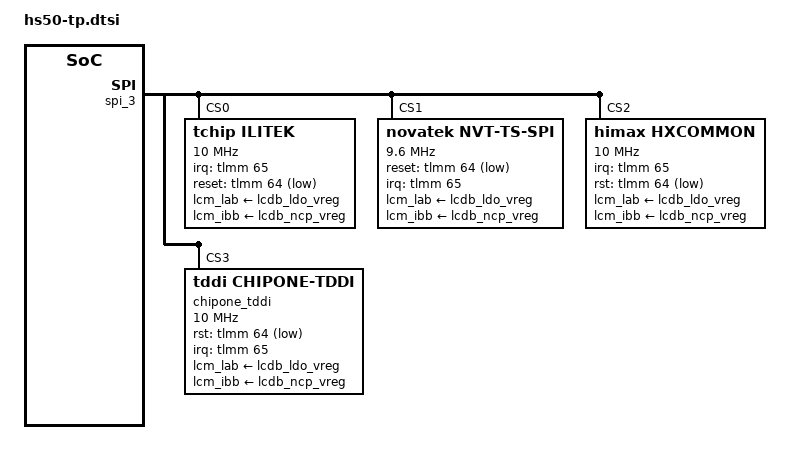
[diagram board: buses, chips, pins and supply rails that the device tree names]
&i2c_3{
	status = "disable";
};
&spi_3{
	status = "ok";
	ilitek@0{
		compatible = "tchip,ilitek";
		reg = <0x0>;
		/* HS70 add for SR-ZQL1871-01-177 by gaozhengwei at 2019/11/02 start */
		lcm_lab-supply = <&lcdb_ldo_vreg>;//Adding Power Properties
		lcm_ibb-supply = <&lcdb_ncp_vreg>;
		/* HS70 add for SR-ZQL1871-01-177 by gaozhengwei at 2019/11/02 end */
		spi-max-frequency = <10000000>;
		interrupt-parent = <&tlmm>;
		interrupts = <65 0x02>;
		touch,irq-gpio = <&tlmm 65 0x02>;
		touch,reset-gpio = <&tlmm 64 0x01>;
		/* HS70 code for HS70-133 by liufurong at 2019/10/31 start */
		pinctrl-names = "default","int-output-high","int-output-low","int-input";
		pinctrl-0 = <&ts_int_default>;
		pinctrl-1 = <&ts_int_output_high>;
		pinctrl-2 = <&ts_int_output_low>;
		pinctrl-3 = <&ts_int_input>;
		/* HS70 code for HS70-133 by liufurong at 2019/10/31 end */
	};
	/*HS50 code for SR-QL3095-01-358 by yuanliding at 2020/07/31 start*/
	/* Novatek device tree node */
	novatek@1 {
		compatible = "novatek,NVT-ts-spi";
		reg = <1>; //Same as CS ID
		status = "ok";

		spi-max-frequency = <9600000>;	//4800000,9600000,15000000,19200000
		novatek,reset-gpio = <&tlmm 64 0x01>;
		novatek,irq-gpio = <&tlmm 65 0x02>;
		lcm_lab-supply = <&lcdb_ldo_vreg>;//Adding Power Properties
		lcm_ibb-supply = <&lcdb_ncp_vreg>;

		/* 525 */
		//novatek,swrst-n8-addr = <0x01F01A>;

		/* 672A, 525B, 675, 526, 672C */
		novatek,swrst-n8-addr = <0x03F0FE>;
		novatek,spi-rd-fast-addr = <0x03F310>;

		/* MP */
		novatek,mp-support-dt;

		novatek-mp-criteria-7211@0 {
			#address-cells = <1>;
			#size-cells = <0>;
			compatible = "novatek-mp-criteria-7211";

			/* MP Config */
			IC_X_CFG_SIZE = <18>;
			IC_Y_CFG_SIZE = <32>;
			IC_KEY_CFG_SIZE = <4>;
			X_Channel = <18>;
			Y_Channel = <32>;
			AIN_X = <0 1 2 3 4 5 6 7 8 9 10 11 12 13 14 15 16 17>;
			AIN_Y = <0 1 2 3 4 5 6 7 8 9 10 11 12 13 14 15 16 17
						18 19 20 21 22 23 24 25 26 27 28 29 30 31>;
			AIN_KEY = <0 1 2 0xFF>;

			/* MP Criteria */
			PS_Config_Lmt_Short_Rawdata_P = <
				14008 14008 14008 14008 14008 14008 14008 14008 14008 14008 14008 14008 14008 14008 14008 14008 14008 14008
				14008 14008 14008 14008 14008 14008 14008 14008 14008 14008 14008 14008 14008 14008 14008 14008 14008 14008
				14008 14008 14008 14008 14008 14008 14008 14008 14008 14008 14008 14008 14008 14008 14008 14008 14008 14008
				14008 14008 14008 14008 14008 14008 14008 14008 14008 14008 14008 14008 14008 14008 14008 14008 14008 14008
				14008 14008 14008 14008 14008 14008 14008 14008 14008 14008 14008 14008 14008 14008 14008 14008 14008 14008
				14008 14008 14008 14008 14008 14008 14008 14008 14008 14008 14008 14008 14008 14008 14008 14008 14008 14008
				14008 14008 14008 14008 14008 14008 14008 14008 14008 14008 14008 14008 14008 14008 14008 14008 14008 14008
				14008 14008 14008 14008 14008 14008 14008 14008 14008 14008 14008 14008 14008 14008 14008 14008 14008 14008
				14008 14008 14008 14008 14008 14008 14008 14008 14008 14008 14008 14008 14008 14008 14008 14008 14008 14008
				14008 14008 14008 14008 14008 14008 14008 14008 14008 14008 14008 14008 14008 14008 14008 14008 14008 14008
				14008 14008 14008 14008 14008 14008 14008 14008 14008 14008 14008 14008 14008 14008 14008 14008 14008 14008
				14008 14008 14008 14008 14008 14008 14008 14008 14008 14008 14008 14008 14008 14008 14008 14008 14008 14008
				14008 14008 14008 14008 14008 14008 14008 14008 14008 14008 14008 14008 14008 14008 14008 14008 14008 14008
				14008 14008 14008 14008 14008 14008 14008 14008 14008 14008 14008 14008 14008 14008 14008 14008 14008 14008
				14008 14008 14008 14008 14008 14008 14008 14008 14008 14008 14008 14008 14008 14008 14008 14008 14008 14008
				14008 14008 14008 14008 14008 14008 14008 14008 14008 14008 14008 14008 14008 14008 14008 14008 14008 14008
				14008 14008 14008 14008 14008 14008 14008 14008 14008 14008 14008 14008 14008 14008 14008 14008 14008 14008
				14008 14008 14008 14008 14008 14008 14008 14008 14008 14008 14008 14008 14008 14008 14008 14008 14008 14008
				14008 14008 14008 14008 14008 14008 14008 14008 14008 14008 14008 14008 14008 14008 14008 14008 14008 14008
				14008 14008 14008 14008 14008 14008 14008 14008 14008 14008 14008 14008 14008 14008 14008 14008 14008 14008
				14008 14008 14008 14008 14008 14008 14008 14008 14008 14008 14008 14008 14008 14008 14008 14008 14008 14008
				14008 14008 14008 14008 14008 14008 14008 14008 14008 14008 14008 14008 14008 14008 14008 14008 14008 14008
				14008 14008 14008 14008 14008 14008 14008 14008 14008 14008 14008 14008 14008 14008 14008 14008 14008 14008
				14008 14008 14008 14008 14008 14008 14008 14008 14008 14008 14008 14008 14008 14008 14008 14008 14008 14008
				14008 14008 14008 14008 14008 14008 14008 14008 14008 14008 14008 14008 14008 14008 14008 14008 14008 14008
				14008 14008 14008 14008 14008 14008 14008 14008 14008 14008 14008 14008 14008 14008 14008 14008 14008 14008
				14008 14008 14008 14008 14008 14008 14008 14008 14008 14008 14008 14008 14008 14008 14008 14008 14008 14008
				14008 14008 14008 14008 14008 14008 14008 14008 14008 14008 14008 14008 14008 14008 14008 14008 14008 14008
				14008 14008 14008 14008 14008 14008 14008 14008 14008 14008 14008 14008 14008 14008 14008 14008 14008 14008
				14008 14008 14008 14008 14008 14008 14008 14008 14008 14008 14008 14008 14008 14008 14008 14008 14008 14008
				14008 14008 14008 14008 14008 14008 14008 14008 14008 14008 14008 14008 14008 14008 14008 14008 14008 14008
				14008 14008 14008 14008 14008 14008 14008 14008 14008 14008 14008 14008 14008 14008 14008 14008 14008 14008
				14008 14008 14008>;

			PS_Config_Lmt_Short_Rawdata_N = <
				11376	11376	11376	11376	11376	11376	11376	11376	11376	11376	11376	11376	11376	11376	11376	11376	11376	11376
				11376	11376	11376	11376	11376	11376	11376	11376	11376	11376	11376	11376	11376	11376	11376	11376	11376	11376
				11376	11376	11376	11376	11376	11376	11376	11376	11376	11376	11376	11376	11376	11376	11376	11376	11376	11376
				11376	11376	11376	11376	11376	11376	11376	11376	11376	11376	11376	11376	11376	11376	11376	11376	11376	11376
				11376	11376	11376	11376	11376	11376	11376	11376	11376	11376	11376	11376	11376	11376	11376	11376	11376	11376
				11376	11376	11376	11376	11376	11376	11376	11376	11376	11376	11376	11376	11376	11376	11376	11376	11376	11376
				11376	11376	11376	11376	11376	11376	11376	11376	11376	11376	11376	11376	11376	11376	11376	11376	11376	11376
				11376	11376	11376	11376	11376	11376	11376	11376	11376	11376	11376	11376	11376	11376	11376	11376	11376	11376
				11376	11376	11376	11376	11376	11376	11376	11376	11376	11376	11376	11376	11376	11376	11376	11376	11376	11376
				11376	11376	11376	11376	11376	11376	11376	11376	11376	11376	11376	11376	11376	11376	11376	11376	11376	11376
				11376	11376	11376	11376	11376	11376	11376	11376	11376	11376	11376	11376	11376	11376	11376	11376	11376	11376
				11376	11376	11376	11376	11376	11376	11376	11376	11376	11376	11376	11376	11376	11376	11376	11376	11376	11376
				11376	11376	11376	11376	11376	11376	11376	11376	11376	11376	11376	11376	11376	11376	11376	11376	11376	11376
				11376	11376	11376	11376	11376	11376	11376	11376	11376	11376	11376	11376	11376	11376	11376	11376	11376	11376
				11376	11376	11376	11376	11376	11376	11376	11376	11376	11376	11376	11376	11376	11376	11376	11376	11376	11376
				11376	11376	11376	11376	11376	11376	11376	11376	11376	11376	11376	11376	11376	11376	11376	11376	11376	11376
				11376	11376	11376	11376	11376	11376	11376	11376	11376	11376	11376	11376	11376	11376	11376	11376	11376	11376
				11376	11376	11376	11376	11376	11376	11376	11376	11376	11376	11376	11376	11376	11376	11376	11376	11376	11376
				11376	11376	11376	11376	11376	11376	11376	11376	11376	11376	11376	11376	11376	11376	11376	11376	11376	11376
				11376	11376	11376	11376	11376	11376	11376	11376	11376	11376	11376	11376	11376	11376	11376	11376	11376	11376
				11376	11376	11376	11376	11376	11376	11376	11376	11376	11376	11376	11376	11376	11376	11376	11376	11376	11376
				11376	11376	11376	11376	11376	11376	11376	11376	11376	11376	11376	11376	11376	11376	11376	11376	11376	11376
				11376	11376	11376	11376	11376	11376	11376	11376	11376	11376	11376	11376	11376	11376	11376	11376	11376	11376
				11376	11376	11376	11376	11376	11376	11376	11376	11376	11376	11376	11376	11376	11376	11376	11376	11376	11376
				11376	11376	11376	11376	11376	11376	11376	11376	11376	11376	11376	11376	11376	11376	11376	11376	11376	11376
				11376	11376	11376	11376	11376	11376	11376	11376	11376	11376	11376	11376	11376	11376	11376	11376	11376	11376
				11376	11376	11376	11376	11376	11376	11376	11376	11376	11376	11376	11376	11376	11376	11376	11376	11376	11376
				11376	11376	11376	11376	11376	11376	11376	11376	11376	11376	11376	11376	11376	11376	11376	11376	11376	11376
				11376	11376	11376	11376	11376	11376	11376	11376	11376	11376	11376	11376	11376	11376	11376	11376	11376	11376
				11376	11376	11376	11376	11376	11376	11376	11376	11376	11376	11376	11376	11376	11376	11376	11376	11376	11376
				11376	11376	11376	11376	11376	11376	11376	11376	11376	11376	11376	11376	11376	11376	11376	11376	11376	11376
				11376	11376	11376	11376	11376	11376	11376	11376	11376	11376	11376	11376	11376	11376	11376	11376	11376	11376
				10000 10000 10000>;

			PS_Config_Lmt_Open_Rawdata_P = <
				3259	3344	3360	3420	3465	3465	3504	3507	65535	65535	3434	3428	3393	3396	3402	3399	3395	3301
				3178	3266	3334	3410	3476	3486	3486	3487	3462	3453	3493	3486	3487	3477	3466	3449	3395	3299
				3264	3341	3409	3491	3557	3568	3565	3570	3535	3416	3456	3458	3459	3453	3442	3431	3375	3306
				3242	3305	3371	3453	3525	3539	3537	3540	3504	3459	3505	3505	3507	3502	3493	3480	3432	3369
				3285	3354	3420	3502	3572	3586	3582	3586	3546	3421	3466	3467	3467	3465	3452	3439	3396	3337
				3260	3320	3383	3467	3540	3563	3563	3567	3528	3480	3528	3529	3530	3529	3515	3501	3463	3403
				3288	3383	3431	3467	3488	3497	3516	3518	3515	3565	3568	3572	3553	3530	3449	3357	3281	3189
				3311	3402	3451	3486	3502	3516	3526	3535	3532	3582	3585	3582	3571	3558	3486	3395	3322	3235
				3291	3382	3430	3467	3484	3500	3504	3511	3508	3560	3565	3563	3558	3547	3477	3385	3315	3231
				3327	3416	3469	3502	3521	3536	3540	3542	3537	3593	3602	3606	3602	3593	3521	3430	3361	3276
				3343	3425	3481	3516	3530	3542	3549	3547	3544	3588	3595	3598	3595	3589	3528	3442	3376	3295
				3381	3460	3518	3554	3570	3584	3585	3586	3585	3626	3633	3634	3637	3630	3571	3487	3421	3343
				3383	3463	3539	3571	3592	3600	3605	3606	3607	3619	3623	3623	3624	3620	3565	3487	3404	3327
				3407	3488	3563	3598	3610	3623	3626	3627	3627	3652	3658	3661	3661	3656	3612	3532	3449	3372
				3407	3481	3551	3582	3593	3602	3607	3610	3607	3640	3648	3651	3648	3651	3606	3537	3460	3388
				3425	3504	3571	3607	3617	3630	3630	3634	3630	3661	3668	3672	3675	3673	3637	3570	3493	3421
				3434	3509	3577	3607	3620	3628	3626	3628	3626	3628	3640	3642	3644	3644	3610	3546	3472	3403
				3463	3536	3598	3631	3642	3649	3647	3649	3644	3669	3679	3683	3686	3684	3655	3593	3523	3458
				3473	3540	3603	3628	3642	3651	3651	3647	3645	3640	3654	3658	3663	3661	3638	3584	3523	3456
				3509	3574	3633	3663	3673	3677	3677	3676	3673	3668	3682	3687	3691	3691	3675	3619	3558	3494
				3502	3565	3623	3652	3662	3668	3665	3662	3656	3631	3648	3649	3655	3654	3641	3593	3537	3477
				3505	3563	3617	3647	3654	3661	3658	3655	3651	3670	3687	3690	3696	3696	3689	3641	3586	3529
				3544	3605	3648	3689	3697	3704	3700	3696	3687	3630	3648	3654	3659	3658	3659	3631	3589	3539
				3528	3582	3626	3662	3673	3680	3676	3673	3665	3669	3687	3691	3698	3698	3700	3677	3637	3591
				3556	3603	3642	3679	3691	3696	3691	3689	3682	3627	3644	3648	3654	3654	3656	3640	3599	3560
				3539	3585	3623	3656	3670	3672	3669	3663	3658	3672	3689	3696	3701	3704	3705	3693	3658	3624
				3585	3630	3662	3693	3705	3707	3708	3704	3698	3630	3642	3648	3645	3649	3649	3638	3609	3577
				3577	3617	3652	3677	3690	3691	3691	3686	3683	3694	3708	3715	3715	3718	3718	3712	3683	3655
				3617	3656	3683	3705	3717	3717	3714	3711	3708	3648	3662	3669	3669	3673	3675	3672	3647	3617
				3602	3638	3662	3680	3690	3691	3690	3684	3680	3686	3698	3705	3705	3710	3714	3712	3693	3673
				2872	3672	3690	3701	3708	3708	3705	3700	3698	3645	3659	3665	3668	3672	3675	3673	3659	2854
				2989	3592	3672	3672	3679	3683	3680	3677	3696	3728	3724	3726	3729	3731	3731	3731	3628	3024
				5120 5120 5120>;

			PS_Config_Lmt_Open_Rawdata_N = <
				1396	1433	1440	1465	1485	1485	1501	1503	(-65535)	(-65535)	1471	1469	1454	1455	1458	1456	1455	1414
				1362	1399	1429	1461	1489	1494	1494	1494	1483	1480	1497	1494	1494	1490	1485	1478	1455	1414        
				1399	1432	1461	1496	1524	1529	1528	1530	1515	1464	1481	1482	1482	1480	1475	1470	1446	1417        
				1389	1416	1444	1480	1510	1516	1516	1517	1501	1482	1502	1502	1503	1501	1497	1491	1471	1444        
				1408	1437	1465	1501	1531	1537	1535	1537	1519	1466	1485	1486	1486	1485	1479	1474	1455	1430        
				1397	1423	1450	1486	1517	1527	1527	1528	1512	1491	1512	1512	1513	1512	1506	1500	1484	1458        
				1409	1450	1470	1486	1495	1498	1507	1507	1506	1528	1529	1531	1522	1513	1478	1438	1406	1366        
				1419	1458	1479	1494	1501	1507	1511	1515	1513	1535	1536	1535	1530	1525	1494	1455	1423	1386        
				1410	1449	1470	1486	1493	1500	1501	1504	1503	1525	1528	1527	1525	1520	1490	1450	1420	1384        
				1426	1464	1486	1501	1509	1515	1517	1518	1516	1540	1543	1545	1543	1540	1509	1470	1440	1404        
				1432	1468	1492	1507	1513	1518	1521	1520	1519	1537	1540	1542	1540	1538	1512	1475	1447	1412        
				1449	1483	1507	1523	1530	1536	1536	1537	1536	1554	1557	1557	1558	1555	1530	1494	1466	1432        
				1450	1484	1516	1530	1539	1543	1545	1545	1546	1551	1552	1552	1553	1551	1528	1494	1459	1426        
				1460	1495	1527	1542	1547	1552	1554	1554	1554	1565	1567	1569	1569	1567	1548	1513	1478	1445        
				1460	1492	1522	1535	1540	1543	1546	1547	1546	1560	1563	1564	1563	1564	1545	1516	1483	1452        
				1468	1501	1530	1546	1550	1555	1555	1557	1555	1569	1572	1573	1575	1574	1558	1530	1497	1466        
				1471	1504	1533	1546	1551	1555	1554	1555	1554	1555	1560	1561	1561	1561	1547	1519	1488	1458        
				1484	1515	1542	1556	1561	1564	1563	1564	1561	1572	1576	1578	1579	1579	1566	1540	1510	1482        
				1488	1517	1544	1555	1561	1564	1564	1563	1562	1560	1566	1567	1570	1569	1559	1536	1510	1481        
				1504	1531	1557	1570	1574	1576	1576	1575	1574	1572	1578	1580	1582	1582	1575	1551	1525	1497        
				1501	1528	1552	1565	1569	1572	1570	1569	1567	1556	1563	1564	1566	1566	1560	1540	1516	1490        
				1502	1527	1550	1563	1566	1569	1567	1566	1564	1573	1580	1581	1584	1584	1581	1560	1537	1512        
				1519	1545	1563	1581	1584	1587	1585	1584	1580	1555	1563	1566	1568	1567	1568	1556	1538	1516        
				1512	1535	1554	1569	1574	1577	1575	1574	1570	1572	1580	1582	1585	1585	1585	1576	1558	1539        
				1524	1544	1561	1576	1582	1584	1582	1581	1578	1554	1561	1563	1566	1566	1567	1560	1542	1525        
				1516	1536	1552	1567	1573	1573	1572	1570	1567	1573	1581	1584	1586	1587	1588	1582	1567	1553        
				1536	1555	1569	1582	1588	1588	1589	1587	1585	1555	1561	1563	1562	1564	1564	1559	1546	1533        
				1533	1550	1565	1576	1581	1582	1582	1579	1578	1583	1589	1592	1592	1593	1593	1591	1578	1566        
				1550	1567	1578	1588	1593	1593	1591	1590	1589	1563	1569	1572	1572	1574	1575	1573	1563	1550        
				1543	1559	1569	1577	1581	1582	1581	1579	1577	1579	1585	1588	1588	1590	1591	1591	1582	1574        
				1231	1573	1581	1586	1589	1589	1588	1585	1585	1562	1568	1570	1572	1573	1575	1574	1568	1223        
				1281	1539	1573	1573	1576	1578	1577	1576	1584	1597	1596	1597	1598	1599	1599	1599	1555	1296        
				(-511) (-511) (-511)>;

			PS_Config_Lmt_FW_Rawdata_P = <
				2255	2245	2235	2252	2247	2251	2238	2248	65535	65535	2248	2228	2247	2240	2247	2256	2256	2238
				2245	2269	2249	2251	2238	2238	2237	2228	2234	2252	2249	2241	2245	2255	2262	2252	2254	2233
				2255	2226	2231	2234	2237	2226	2235	2241	2230	2251	2231	2241	2230	2235	2228	2237	2259	2228
				2245	2247	2245	2245	2252	2251	2245	2235	2251	2233	2209	2217	2223	2230	2228	2223	2234	2249
				2245	2251	2256	2254	2249	2252	2256	2241	2241	2240	2248	2244	2238	2219	2217	2221	2255	2231
				2235	2245	2231	2242	2241	2242	2242	2266	2279	2241	2247	2251	2259	2245	2270	2259	2282	2219
				2252	2227	2251	2240	2242	2234	2216	2241	2214	2248	2227	2228	2221	2235	2256	2230	2252	2237
				2213	2259	2249	2266	2254	2237	2254	2256	2244	2241	2241	2247	2262	2235	2233	2248	2241	2251
				2235	2242	2254	2258	2252	2256	2256	2266	2262	2256	2254	2252	2235	2262	2252	2251	2248	2244
				2255	2245	2228	2240	2237	2221	2228	2223	2240	2261	2255	2245	2244	2231	2247	2248	2237	2245
				2241	2244	2234	2242	2241	2242	2234	2248	2242	2256	2247	2254	2254	2251	2244	2238	2254	2259
				2235	2256	2237	2237	2235	2245	2230	2226	2255	2235	2237	2247	2242	2224	2220	2247	2226	2244
				2235	2235	2254	2252	2241	2238	2245	2244	2247	2238	2263	2269	2268	2252	2249	2238	2244	2226
				2252	2241	2233	2234	2228	2237	2226	2233	2247	2233	2255	2245	2242	2255	2241	2235	2256	2226
				2230	2238	2242	2237	2230	2221	2230	2238	2235	2230	2231	2237	2237	2230	2217	2228	2247	2254
				2249	2231	2254	2244	2244	2252	2248	2259	2249	2233	2233	2228	2224	2234	2248	2252	2212	2251
				2258	2242	2247	2258	2244	2231	2233	2248	2241	2226	2255	2266	2269	2249	2241	2244	2251	2241
				2261	2254	2228	2233	2234	2244	2240	2228	2240	2249	2258	2237	2242	2270	2259	2263	2244	2241
				2245	2224	2237	2241	2234	2228	2235	2235	2238	2241	2247	2234	2220	2249	2245	2244	2245	2235
				2220	2251	2252	2238	2240	2231	2230	2245	2228	2252	2228	2241	2244	2241	2230	2235	2230	2235
				2227	2235	2251	2237	2247	2240	2247	2247	2237	2273	2245	2258	2244	2251	2233	2241	2244	2262
				2223	2249	2244	2238	2234	2230	2234	2228	2223	2255	2252	2263	2270	2249	2256	2252	2258	2268
				2263	2220	2233	2226	2242	2230	2235	2235	2234	2245	2238	2241	2230	2251	2242	2258	2234	2248
				2262	2227	2247	2248	2255	2258	2256	2247	2227	2235	2231	2242	2238	2213	2227	2213	2234	2221
				2262	2252	2244	2258	2247	2235	2247	2245	2242	2252	2240	2217	2205	2240	2240	2244	2224	2266
				2259	2237	2238	2234	2244	2245	2248	2255	2247	2242	2261	2259	2255	2252	2242	2248	2245	2261
				2238	2238	2256	2256	2256	2268	2268	2235	2249	2240	2235	2248	2248	2242	2247	2251	2252	2242
				2238	2247	2216	2245	2231	2224	2226	2224	2254	2244	2252	2252	2248	2247	2254	2249	2235	2242
				2268	2224	2224	2234	2233	2228	2227	2226	2262	2256	2235	2249	2245	2240	2234	2227	2263	2263
				2234	2263	2251	2245	2258	2251	2240	2242	2241	2223	2240	2245	2245	2238	2228	2227	2240	2261
				2256	2251	2249	2241	2261	2258	2258	2256	2255	2266	2227	2231	2233	2219	2237	2241	2240	2237
				2254	2248	2258	2247	2237	2231	2219	2227	2247	2255	2251	2254	2248	2284	2263	2269	2265	2231
				2560 2560 2560>;

			PS_Config_Lmt_FW_Rawdata_N = <
				966	962	958	965	963	964	959	963	(-65535)	(-65535)	963	955	963	960	963	967	967	959
				962	972	964	964	959	959	958	955	957	965	964	960	962	966	969	965	966	957            
				966	954	956	957	958	954	958	960	955	964	956	960	955	958	955	958	968	955            
				962	963	962	962	965	964	962	958	964	957	946	950	952	955	955	952	957	964            
				962	964	967	966	964	965	967	960	960	960	963	961	959	951	950	952	966	956            
				958	962	956	961	960	961	961	971	976	960	963	964	968	962	973	968	978	951            
				965	954	964	960	961	957	949	960	949	963	954	955	952	958	967	955	965	958            
				948	968	964	971	966	958	966	967	961	960	960	963	969	958	957	963	960	964            
				958	961	966	967	965	967	967	971	969	967	966	965	958	969	965	964	963	961            
				966	962	955	960	958	952	955	952	960	969	966	962	961	956	963	963	958	962            
				960	961	957	961	960	961	957	963	961	967	963	966	966	964	961	959	966	968            
				958	967	958	958	958	962	955	954	966	958	958	963	961	953	951	963	954	961            
				958	958	966	965	960	959	962	961	963	959	970	972	972	965	964	959	961	954            
				965	960	957	957	955	958	954	957	963	957	966	962	961	966	960	958	967	954            
				955	959	961	958	955	952	955	959	958	955	956	958	958	955	950	955	963	966            
				964	956	966	961	961	965	963	968	964	957	957	955	953	957	963	965	948	964            
				967	961	963	967	961	956	957	963	960	954	966	971	972	964	960	961	964	960            
				969	966	955	957	957	961	960	955	960	964	967	958	961	973	968	970	961	960            
				962	953	958	960	957	955	958	958	959	960	963	957	951	964	962	961	962	958            
				951	964	965	959	960	956	955	962	955	965	955	960	961	960	955	958	955	958            
				954	958	964	958	963	960	963	963	958	974	962	967	961	964	957	960	961	969            
				952	964	961	959	957	955	957	955	952	966	965	970	973	964	967	965	967	972            
				970	951	957	954	961	955	958	958	957	962	959	960	955	964	961	967	957	963            
				969	954	963	963	966	967	967	963	954	958	956	961	959	948	954	948	957	952            
				969	965	961	967	963	958	963	962	961	965	960	950	945	960	960	961	953	971            
				968	958	959	957	961	962	963	966	963	961	969	968	966	965	961	963	962	969            
				959	959	967	967	967	972	972	958	964	960	958	963	963	961	963	964	965	961            
				959	963	949	962	956	953	954	953	966	961	965	965	963	963	966	964	958	961            
				972	953	953	957	957	955	954	954	969	967	958	964	962	960	957	954	970	970            
				957	970	964	962	967	964	960	961	960	952	960	962	962	959	955	954	960	969            
				967	964	964	960	969	967	967	967	966	971	954	956	957	951	958	960	960	958            
				966	963	967	963	958	956	951	954	963	966	964	966	963	979	970	972	970	956            
				240 240 240>;

			PS_Config_Lmt_FW_CC_P = <
				93	96	96	96	97	97	97	96	65535	65535	99	100	100	100	99	99	99	97
				95	95	95	95	95	95	95	95	97	102	99	99	99	99	99	99	100	100   
				96	95	95	95	95	95	95	96	99	100	99	99	99	99	99	99	99	100   
				96	95	95	95	95	95	95	95	97	102	99	99	99	99	99	99	100	102   
				96	95	95	96	96	96	96	96	99	102	99	99	99	99	99	99	99	100   
				96	95	95	96	96	96	96	96	99	103	100	100	100	100	100	100	100	102   
				97	96	96	96	96	96	96	96	99	102	100	100	100	99	99	99	99	100   
				100	99	99	99	99	99	99	99	102	104	103	103	103	102	102	102	102	103   
				97	96	96	96	96	96	96	96	99	102	99	99	100	99	99	99	99	100   
				100	99	97	97	97	97	97	97	100	104	102	102	102	102	102	102	102	103   
				97	96	96	96	96	95	96	96	97	102	99	99	99	99	99	99	99	100   
				100	97	97	97	97	97	97	97	100	104	102	102	102	102	102	102	102	103   
				97	96	96	96	96	95	96	96	97	102	99	99	99	99	99	99	99	100   
				100	99	99	99	99	99	99	99	102	104	102	102	102	102	102	102	102	103   
				97	96	96	96	96	96	96	96	99	102	99	99	99	99	99	99	99	100   
				99	97	97	97	97	97	97	97	100	104	102	102	102	102	102	102	102	103   
				97	96	96	96	95	95	95	95	97	102	99	99	99	99	99	99	99	100   
				99	97	97	97	97	97	97	97	100	104	102	102	102	102	102	102	102	104   
				99	96	96	96	96	96	96	96	99	100	99	99	99	99	99	99	99	100   
				100	99	97	99	97	97	97	97	100	103	102	102	102	102	102	102	102	103   
				97	96	96	96	96	96	96	96	97	102	99	99	99	99	99	99	99	102   
				100	99	99	99	99	99	99	99	102	103	102	102	102	102	102	102	102	103   
				97	95	95	95	95	95	95	95	97	99	97	97	97	97	97	97	97	100   
				96	95	95	95	95	95	95	95	97	100	99	99	99	99	99	99	99	102   
				96	95	95	95	95	95	95	95	97	100	97	97	99	97	97	97	99	100   
				97	96	95	96	95	95	95	95	97	100	99	99	99	99	99	99	99	102   
				96	95	95	95	95	95	95	95	97	99	97	97	97	97	97	97	97	99    
				97	96	96	96	96	95	95	95	97	102	99	99	99	99	99	99	100	102   
				97	96	95	96	95	95	95	95	97	100	97	97	97	97	97	97	99	100   
				97	95	95	95	95	95	95	95	97	102	99	99	99	99	99	99	99	102   
				91	95	95	95	95	95	95	95	97	99	97	97	97	97	97	97	97	92    
				91	95	95	93	93	93	95	95	97	102	99	99	99	99	99	99	99	95    
				314 314 314>;

			PS_Config_Lmt_FW_CC_N = <
				42	43	43	43	44	44	44	43	(-65535)	(-65535)	44	45	45	45	44	44	44	44
				42	42	42	42	42	42	42	42	44	45	44	44	44	44	44	44	45	45            
				43	42	42	42	42	42	42	43	44	45	44	44	44	44	44	44	44	45            
				43	42	42	42	42	42	42	42	44	45	44	44	44	44	44	44	45	45            
				43	42	42	43	43	43	43	43	44	45	44	44	44	44	44	44	44	45            
				43	42	42	43	43	43	43	43	44	46	45	45	45	45	45	45	45	45            
				44	43	43	43	43	43	43	43	44	45	45	45	45	44	44	44	44	45            
				45	44	44	44	44	44	44	44	45	47	46	46	46	45	45	45	45	46            
				44	43	43	43	43	43	43	43	44	45	44	44	45	44	44	44	44	45            
				45	44	44	44	44	44	44	44	45	47	45	45	45	45	45	45	45	46            
				44	43	43	43	43	42	43	43	44	45	44	44	44	44	44	44	44	45            
				45	44	44	44	44	44	44	44	45	47	45	45	45	45	45	45	45	46            
				44	43	43	43	43	42	43	43	44	45	44	44	44	44	44	44	44	45            
				45	44	44	44	44	44	44	44	45	47	45	45	45	45	45	45	45	46            
				44	43	43	43	43	43	43	43	44	45	44	44	44	44	44	44	44	45            
				44	44	44	44	44	44	44	44	45	47	45	45	45	45	45	45	45	46            
				44	43	43	43	42	42	42	42	44	45	44	44	44	44	44	44	44	45            
				44	44	44	44	44	44	44	44	45	47	45	45	45	45	45	45	45	47            
				44	43	43	43	43	43	43	43	44	45	44	44	44	44	44	44	44	45            
				45	44	44	44	44	44	44	44	45	46	45	45	45	45	45	45	45	46            
				44	43	43	43	43	43	43	43	44	45	44	44	44	44	44	44	44	45            
				45	44	44	44	44	44	44	44	45	46	45	45	45	45	45	45	45	46            
				44	42	42	42	42	42	42	42	44	44	44	44	44	44	44	44	44	45            
				43	42	42	42	42	42	42	42	44	45	44	44	44	44	44	44	44	45            
				43	42	42	42	42	42	42	42	44	45	44	44	44	44	44	44	44	45            
				44	43	42	43	42	42	42	42	44	45	44	44	44	44	44	44	44	45            
				43	42	42	42	42	42	42	42	44	44	44	44	44	44	44	44	44	44            
				44	43	43	43	43	42	42	42	44	45	44	44	44	44	44	44	45	45            
				44	43	42	43	42	42	42	42	44	45	44	44	44	44	44	44	44	45            
				44	42	42	42	42	42	42	42	44	45	44	44	44	44	44	44	44	45            
				40	42	42	42	42	42	42	42	44	44	44	44	44	44	44	44	44	41            
				40	42	42	42	42	42	42	42	44	45	44	44	44	44	44	44	44	42            
				0 0 0>;

			PS_Config_Lmt_FW_Diff_P = <
				50	50	50	50	50	50	50	50	65535	65535	50	50	50	50	50	50	50	50
				50	50	50	50	50	50	50	50	50	50	50	50	50	50	50	50	50	50    
				50	50	50	50	50	50	50	50	50	50	50	50	50	50	50	50	50	50    
				50	50	50	50	50	50	50	50	50	50	50	50	50	50	50	50	50	50    
				50	50	50	50	50	50	50	50	50	50	50	50	50	50	50	50	50	50    
				50	50	50	50	50	50	50	50	50	50	50	50	50	50	50	50	50	50    
				50	50	50	50	50	50	50	50	50	50	50	50	50	50	50	50	50	50    
				50	50	50	50	50	50	50	50	50	50	50	50	50	50	50	50	50	50    
				50	50	50	50	50	50	50	50	50	50	50	50	50	50	50	50	50	50    
				50	50	50	50	50	50	50	50	50	50	50	50	50	50	50	50	50	50    
				50	50	50	50	50	50	50	50	50	50	50	50	50	50	50	50	50	50    
				50	50	50	50	50	50	50	50	50	50	50	50	50	50	50	50	50	50    
				50	50	50	50	50	50	50	50	50	50	50	50	50	50	50	50	50	50    
				50	50	50	50	50	50	50	50	50	50	50	50	50	50	50	50	50	50    
				50	50	50	50	50	50	50	50	50	50	50	50	50	50	50	50	50	50    
				50	50	50	50	50	50	50	50	50	50	50	50	50	50	50	50	50	50    
				50	50	50	50	50	50	50	50	50	50	50	50	50	50	50	50	50	50    
				50	50	50	50	50	50	50	50	50	50	50	50	50	50	50	50	50	50    
				50	50	50	50	50	50	50	50	50	50	50	50	50	50	50	50	50	50    
				50	50	50	50	50	50	50	50	50	50	50	50	50	50	50	50	50	50    
				50	50	50	50	50	50	50	50	50	50	50	50	50	50	50	50	50	50    
				50	50	50	50	50	50	50	50	50	50	50	50	50	50	50	50	50	50    
				50	50	50	50	50	50	50	50	50	50	50	50	50	50	50	50	50	50    
				50	50	50	50	50	50	50	50	50	50	50	50	50	50	50	50	50	50    
				50	50	50	50	50	50	50	50	50	50	50	50	50	50	50	50	50	50    
				50	50	50	50	50	50	50	50	50	50	50	50	50	50	50	50	50	50    
				50	50	50	50	50	50	50	50	50	50	50	50	50	50	50	50	50	50    
				50	50	50	50	50	50	50	50	50	50	50	50	50	50	50	50	50	50    
				50	50	50	50	50	50	50	50	50	50	50	50	50	50	50	50	50	50    
				50	50	50	50	50	50	50	50	50	50	50	50	50	50	50	50	50	50    
				50	50	50	50	50	50	50	50	50	50	50	50	50	50	50	50	50	50    
				50	50	50	50	50	50	50	50	50	50	50	50	50	50	50	50	50	50    
				75 75 75>;

			PS_Config_Lmt_FW_Diff_N = <
				(-50)	(-50)	(-50)	(-50)	(-50)	(-50)	(-50)	(-50)	(-65535)	(-65535)	(-50)	(-50)	(-50)	(-50)	(-50)	(-50)	(-50)	(-50)
				(-50)	(-50)	(-50)	(-50)	(-50)	(-50)	(-50)	(-50)	(-50)	(-50)	(-50)	(-50)	(-50)	(-50)	(-50)	(-50)	(-50)	(-50)        
				(-50)	(-50)	(-50)	(-50)	(-50)	(-50)	(-50)	(-50)	(-50)	(-50)	(-50)	(-50)	(-50)	(-50)	(-50)	(-50)	(-50)	(-50)        
				(-50)	(-50)	(-50)	(-50)	(-50)	(-50)	(-50)	(-50)	(-50)	(-50)	(-50)	(-50)	(-50)	(-50)	(-50)	(-50)	(-50)	(-50)        
				(-50)	(-50)	(-50)	(-50)	(-50)	(-50)	(-50)	(-50)	(-50)	(-50)	(-50)	(-50)	(-50)	(-50)	(-50)	(-50)	(-50)	(-50)        
				(-50)	(-50)	(-50)	(-50)	(-50)	(-50)	(-50)	(-50)	(-50)	(-50)	(-50)	(-50)	(-50)	(-50)	(-50)	(-50)	(-50)	(-50)        
				(-50)	(-50)	(-50)	(-50)	(-50)	(-50)	(-50)	(-50)	(-50)	(-50)	(-50)	(-50)	(-50)	(-50)	(-50)	(-50)	(-50)	(-50)        
				(-50)	(-50)	(-50)	(-50)	(-50)	(-50)	(-50)	(-50)	(-50)	(-50)	(-50)	(-50)	(-50)	(-50)	(-50)	(-50)	(-50)	(-50)        
				(-50)	(-50)	(-50)	(-50)	(-50)	(-50)	(-50)	(-50)	(-50)	(-50)	(-50)	(-50)	(-50)	(-50)	(-50)	(-50)	(-50)	(-50)        
				(-50)	(-50)	(-50)	(-50)	(-50)	(-50)	(-50)	(-50)	(-50)	(-50)	(-50)	(-50)	(-50)	(-50)	(-50)	(-50)	(-50)	(-50)        
				(-50)	(-50)	(-50)	(-50)	(-50)	(-50)	(-50)	(-50)	(-50)	(-50)	(-50)	(-50)	(-50)	(-50)	(-50)	(-50)	(-50)	(-50)        
				(-50)	(-50)	(-50)	(-50)	(-50)	(-50)	(-50)	(-50)	(-50)	(-50)	(-50)	(-50)	(-50)	(-50)	(-50)	(-50)	(-50)	(-50)        
				(-50)	(-50)	(-50)	(-50)	(-50)	(-50)	(-50)	(-50)	(-50)	(-50)	(-50)	(-50)	(-50)	(-50)	(-50)	(-50)	(-50)	(-50)        
				(-50)	(-50)	(-50)	(-50)	(-50)	(-50)	(-50)	(-50)	(-50)	(-50)	(-50)	(-50)	(-50)	(-50)	(-50)	(-50)	(-50)	(-50)        
				(-50)	(-50)	(-50)	(-50)	(-50)	(-50)	(-50)	(-50)	(-50)	(-50)	(-50)	(-50)	(-50)	(-50)	(-50)	(-50)	(-50)	(-50)        
				(-50)	(-50)	(-50)	(-50)	(-50)	(-50)	(-50)	(-50)	(-50)	(-50)	(-50)	(-50)	(-50)	(-50)	(-50)	(-50)	(-50)	(-50)        
				(-50)	(-50)	(-50)	(-50)	(-50)	(-50)	(-50)	(-50)	(-50)	(-50)	(-50)	(-50)	(-50)	(-50)	(-50)	(-50)	(-50)	(-50)        
				(-50)	(-50)	(-50)	(-50)	(-50)	(-50)	(-50)	(-50)	(-50)	(-50)	(-50)	(-50)	(-50)	(-50)	(-50)	(-50)	(-50)	(-50)        
				(-50)	(-50)	(-50)	(-50)	(-50)	(-50)	(-50)	(-50)	(-50)	(-50)	(-50)	(-50)	(-50)	(-50)	(-50)	(-50)	(-50)	(-50)        
				(-50)	(-50)	(-50)	(-50)	(-50)	(-50)	(-50)	(-50)	(-50)	(-50)	(-50)	(-50)	(-50)	(-50)	(-50)	(-50)	(-50)	(-50)        
				(-50)	(-50)	(-50)	(-50)	(-50)	(-50)	(-50)	(-50)	(-50)	(-50)	(-50)	(-50)	(-50)	(-50)	(-50)	(-50)	(-50)	(-50)        
				(-50)	(-50)	(-50)	(-50)	(-50)	(-50)	(-50)	(-50)	(-50)	(-50)	(-50)	(-50)	(-50)	(-50)	(-50)	(-50)	(-50)	(-50)        
				(-50)	(-50)	(-50)	(-50)	(-50)	(-50)	(-50)	(-50)	(-50)	(-50)	(-50)	(-50)	(-50)	(-50)	(-50)	(-50)	(-50)	(-50)        
				(-50)	(-50)	(-50)	(-50)	(-50)	(-50)	(-50)	(-50)	(-50)	(-50)	(-50)	(-50)	(-50)	(-50)	(-50)	(-50)	(-50)	(-50)        
				(-50)	(-50)	(-50)	(-50)	(-50)	(-50)	(-50)	(-50)	(-50)	(-50)	(-50)	(-50)	(-50)	(-50)	(-50)	(-50)	(-50)	(-50)        
				(-50)	(-50)	(-50)	(-50)	(-50)	(-50)	(-50)	(-50)	(-50)	(-50)	(-50)	(-50)	(-50)	(-50)	(-50)	(-50)	(-50)	(-50)        
				(-50)	(-50)	(-50)	(-50)	(-50)	(-50)	(-50)	(-50)	(-50)	(-50)	(-50)	(-50)	(-50)	(-50)	(-50)	(-50)	(-50)	(-50)        
				(-50)	(-50)	(-50)	(-50)	(-50)	(-50)	(-50)	(-50)	(-50)	(-50)	(-50)	(-50)	(-50)	(-50)	(-50)	(-50)	(-50)	(-50)        
				(-50)	(-50)	(-50)	(-50)	(-50)	(-50)	(-50)	(-50)	(-50)	(-50)	(-50)	(-50)	(-50)	(-50)	(-50)	(-50)	(-50)	(-50)        
				(-50)	(-50)	(-50)	(-50)	(-50)	(-50)	(-50)	(-50)	(-50)	(-50)	(-50)	(-50)	(-50)	(-50)	(-50)	(-50)	(-50)	(-50)        
				(-50)	(-50)	(-50)	(-50)	(-50)	(-50)	(-50)	(-50)	(-50)	(-50)	(-50)	(-50)	(-50)	(-50)	(-50)	(-50)	(-50)	(-50)        
				(-50)	(-50)	(-50)	(-50)	(-50)	(-50)	(-50)	(-50)	(-50)	(-50)	(-50)	(-50)	(-50)	(-50)	(-50)	(-50)	(-50)	(-50)        
				(-75) (-75) (-75)>;

			PS_Config_Diff_Test_Frame = <50>;
		};

		novatek-mp-criteria-721A@1 {
			#address-cells = <1>;
			#size-cells = <0>;
			compatible = "novatek-mp-criteria-721A";

			/* sec cmd test config */
			open_test_spec = <(-511) 5120>;
			short_test_spec = <10000 14008>;
			diff_test_frame = <50>;

			/* MP Config */
			IC_X_CFG_SIZE = <18>;
			IC_Y_CFG_SIZE = <32>;
			IC_KEY_CFG_SIZE = <4>;
			X_Channel = <18>;
			Y_Channel = <32>;
			AIN_X = <0 1 2 3 4 5 6 7 8 9 10 11 12 13 14 15 16 17>;
			AIN_Y = <0 1 2 3 4 5 6 7 8 9 10 11 12 13 14 15 16 17
						18 19 20 21 22 23 24 25 26 27 28 29 30 31>;
			AIN_KEY = <0 1 2 0xFF>;

			/* MP Criteria */
			PS_Config_Lmt_Short_Rawdata_P = <
				14008 14008 14008 14008 14008 14008 14008 14008 14008 14008 14008 14008 14008 14008 14008 14008 14008 14008
				14008 14008 14008 14008 14008 14008 14008 14008 14008 14008 14008 14008 14008 14008 14008 14008 14008 14008
				14008 14008 14008 14008 14008 14008 14008 14008 14008 14008 14008 14008 14008 14008 14008 14008 14008 14008
				14008 14008 14008 14008 14008 14008 14008 14008 14008 14008 14008 14008 14008 14008 14008 14008 14008 14008
				14008 14008 14008 14008 14008 14008 14008 14008 14008 14008 14008 14008 14008 14008 14008 14008 14008 14008
				14008 14008 14008 14008 14008 14008 14008 14008 14008 14008 14008 14008 14008 14008 14008 14008 14008 14008
				14008 14008 14008 14008 14008 14008 14008 14008 14008 14008 14008 14008 14008 14008 14008 14008 14008 14008
				14008 14008 14008 14008 14008 14008 14008 14008 14008 14008 14008 14008 14008 14008 14008 14008 14008 14008
				14008 14008 14008 14008 14008 14008 14008 14008 14008 14008 14008 14008 14008 14008 14008 14008 14008 14008
				14008 14008 14008 14008 14008 14008 14008 14008 14008 14008 14008 14008 14008 14008 14008 14008 14008 14008
				14008 14008 14008 14008 14008 14008 14008 14008 14008 14008 14008 14008 14008 14008 14008 14008 14008 14008
				14008 14008 14008 14008 14008 14008 14008 14008 14008 14008 14008 14008 14008 14008 14008 14008 14008 14008
				14008 14008 14008 14008 14008 14008 14008 14008 14008 14008 14008 14008 14008 14008 14008 14008 14008 14008
				14008 14008 14008 14008 14008 14008 14008 14008 14008 14008 14008 14008 14008 14008 14008 14008 14008 14008
				14008 14008 14008 14008 14008 14008 14008 14008 14008 14008 14008 14008 14008 14008 14008 14008 14008 14008
				14008 14008 14008 14008 14008 14008 14008 14008 14008 14008 14008 14008 14008 14008 14008 14008 14008 14008
				14008 14008 14008 14008 14008 14008 14008 14008 14008 14008 14008 14008 14008 14008 14008 14008 14008 14008
				14008 14008 14008 14008 14008 14008 14008 14008 14008 14008 14008 14008 14008 14008 14008 14008 14008 14008
				14008 14008 14008 14008 14008 14008 14008 14008 14008 14008 14008 14008 14008 14008 14008 14008 14008 14008
				14008 14008 14008 14008 14008 14008 14008 14008 14008 14008 14008 14008 14008 14008 14008 14008 14008 14008
				14008 14008 14008 14008 14008 14008 14008 14008 14008 14008 14008 14008 14008 14008 14008 14008 14008 14008
				14008 14008 14008 14008 14008 14008 14008 14008 14008 14008 14008 14008 14008 14008 14008 14008 14008 14008
				14008 14008 14008 14008 14008 14008 14008 14008 14008 14008 14008 14008 14008 14008 14008 14008 14008 14008
				14008 14008 14008 14008 14008 14008 14008 14008 14008 14008 14008 14008 14008 14008 14008 14008 14008 14008
				14008 14008 14008 14008 14008 14008 14008 14008 14008 14008 14008 14008 14008 14008 14008 14008 14008 14008
				14008 14008 14008 14008 14008 14008 14008 14008 14008 14008 14008 14008 14008 14008 14008 14008 14008 14008
				14008 14008 14008 14008 14008 14008 14008 14008 14008 14008 14008 14008 14008 14008 14008 14008 14008 14008
				14008 14008 14008 14008 14008 14008 14008 14008 14008 14008 14008 14008 14008 14008 14008 14008 14008 14008
				14008 14008 14008 14008 14008 14008 14008 14008 14008 14008 14008 14008 14008 14008 14008 14008 14008 14008
				14008 14008 14008 14008 14008 14008 14008 14008 14008 14008 14008 14008 14008 14008 14008 14008 14008 14008
				14008 14008 14008 14008 14008 14008 14008 14008 14008 14008 14008 14008 14008 14008 14008 14008 14008 14008
				14008 14008 14008 14008 14008 14008 14008 14008 14008 14008 14008 14008 14008 14008 14008 14008 14008 14008
				14008 14008 14008>;

			PS_Config_Lmt_Short_Rawdata_N = <
				11376	11376	11376	11376	11376	11376	11376	11376	11376	11376	11376	11376	11376	11376	11376	11376	11376	11376
				11376	11376	11376	11376	11376	11376	11376	11376	11376	11376	11376	11376	11376	11376	11376	11376	11376	11376
				11376	11376	11376	11376	11376	11376	11376	11376	11376	11376	11376	11376	11376	11376	11376	11376	11376	11376
				11376	11376	11376	11376	11376	11376	11376	11376	11376	11376	11376	11376	11376	11376	11376	11376	11376	11376
				11376	11376	11376	11376	11376	11376	11376	11376	11376	11376	11376	11376	11376	11376	11376	11376	11376	11376
				11376	11376	11376	11376	11376	11376	11376	11376	11376	11376	11376	11376	11376	11376	11376	11376	11376	11376
				11376	11376	11376	11376	11376	11376	11376	11376	11376	11376	11376	11376	11376	11376	11376	11376	11376	11376
				11376	11376	11376	11376	11376	11376	11376	11376	11376	11376	11376	11376	11376	11376	11376	11376	11376	11376
				11376	11376	11376	11376	11376	11376	11376	11376	11376	11376	11376	11376	11376	11376	11376	11376	11376	11376
				11376	11376	11376	11376	11376	11376	11376	11376	11376	11376	11376	11376	11376	11376	11376	11376	11376	11376
				11376	11376	11376	11376	11376	11376	11376	11376	11376	11376	11376	11376	11376	11376	11376	11376	11376	11376
				11376	11376	11376	11376	11376	11376	11376	11376	11376	11376	11376	11376	11376	11376	11376	11376	11376	11376
				11376	11376	11376	11376	11376	11376	11376	11376	11376	11376	11376	11376	11376	11376	11376	11376	11376	11376
				11376	11376	11376	11376	11376	11376	11376	11376	11376	11376	11376	11376	11376	11376	11376	11376	11376	11376
				11376	11376	11376	11376	11376	11376	11376	11376	11376	11376	11376	11376	11376	11376	11376	11376	11376	11376
				11376	11376	11376	11376	11376	11376	11376	11376	11376	11376	11376	11376	11376	11376	11376	11376	11376	11376
				11376	11376	11376	11376	11376	11376	11376	11376	11376	11376	11376	11376	11376	11376	11376	11376	11376	11376
				11376	11376	11376	11376	11376	11376	11376	11376	11376	11376	11376	11376	11376	11376	11376	11376	11376	11376
				11376	11376	11376	11376	11376	11376	11376	11376	11376	11376	11376	11376	11376	11376	11376	11376	11376	11376
				11376	11376	11376	11376	11376	11376	11376	11376	11376	11376	11376	11376	11376	11376	11376	11376	11376	11376
				11376	11376	11376	11376	11376	11376	11376	11376	11376	11376	11376	11376	11376	11376	11376	11376	11376	11376
				11376	11376	11376	11376	11376	11376	11376	11376	11376	11376	11376	11376	11376	11376	11376	11376	11376	11376
				11376	11376	11376	11376	11376	11376	11376	11376	11376	11376	11376	11376	11376	11376	11376	11376	11376	11376
				11376	11376	11376	11376	11376	11376	11376	11376	11376	11376	11376	11376	11376	11376	11376	11376	11376	11376
				11376	11376	11376	11376	11376	11376	11376	11376	11376	11376	11376	11376	11376	11376	11376	11376	11376	11376
				11376	11376	11376	11376	11376	11376	11376	11376	11376	11376	11376	11376	11376	11376	11376	11376	11376	11376
				11376	11376	11376	11376	11376	11376	11376	11376	11376	11376	11376	11376	11376	11376	11376	11376	11376	11376
				11376	11376	11376	11376	11376	11376	11376	11376	11376	11376	11376	11376	11376	11376	11376	11376	11376	11376
				11376	11376	11376	11376	11376	11376	11376	11376	11376	11376	11376	11376	11376	11376	11376	11376	11376	11376
				11376	11376	11376	11376	11376	11376	11376	11376	11376	11376	11376	11376	11376	11376	11376	11376	11376	11376
				11376	11376	11376	11376	11376	11376	11376	11376	11376	11376	11376	11376	11376	11376	11376	11376	11376	11376
				11376	11376	11376	11376	11376	11376	11376	11376	11376	11376	11376	11376	11376	11376	11376	11376	11376	11376
				10000 10000 10000>;

			PS_Config_Lmt_Open_Rawdata_P = <
				2494	2500	2504	2527	2549	2518	2503	2549	65535	65535	2475	2424	2452	2483	2517	2555	2556	2487
				2332	2338	2373	2427	2478	2472	2457	2443	2412	2392	2422	2430	2454	2459	2472	2480	2444	2378
				2389	2392	2429	2490	2548	2542	2522	2511	2472	2399	2426	2440	2459	2471	2482	2493	2455	2401
				2392	2384	2419	2478	2541	2538	2518	2506	2466	2436	2466	2480	2503	2514	2525	2535	2503	2452
				2417	2412	2447	2511	2574	2567	2546	2536	2493	2406	2434	2447	2468	2482	2490	2500	2473	2424
				2417	2409	2443	2503	2569	2577	2556	2545	2500	2466	2503	2515	2535	2550	2557	2566	2548	2499
				2489	2493	2511	2528	2529	2518	2525	2511	2490	2592	2597	2615	2608	2602	2527	2436	2380	2328
				2517	2524	2546	2564	2560	2555	2548	2541	2520	2633	2640	2651	2655	2657	2585	2492	2437	2381
				2528	2539	2566	2587	2581	2577	2563	2557	2536	2644	2651	2661	2674	2676	2605	2510	2455	2398
				2566	2576	2606	2623	2620	2618	2606	2592	2569	2681	2692	2709	2717	2725	2647	2555	2501	2438
				2598	2609	2641	2658	2651	2646	2633	2616	2598	2696	2703	2718	2731	2738	2674	2581	2527	2465
				2632	2640	2679	2697	2692	2685	2664	2650	2634	2732	2738	2755	2780	2790	2725	2627	2571	2510
				2636	2644	2703	2718	2716	2704	2686	2674	2665	2735	2732	2746	2772	2783	2721	2633	2556	2496
				2669	2681	2739	2762	2749	2744	2723	2711	2702	2780	2781	2794	2818	2830	2783	2693	2618	2553
				2711	2721	2781	2800	2790	2773	2762	2749	2738	2793	2793	2807	2822	2846	2797	2717	2637	2573
				2744	2753	2811	2840	2822	2815	2794	2784	2769	2843	2847	2863	2885	2902	2865	2783	2703	2639
				2765	2770	2832	2847	2840	2832	2815	2802	2783	2840	2844	2860	2882	2899	2867	2793	2711	2648
				2790	2797	2853	2870	2863	2854	2835	2823	2804	2885	2889	2906	2924	2941	2909	2842	2766	2699
				2828	2830	2889	2896	2896	2891	2874	2857	2839	2886	2898	2912	2935	2947	2923	2857	2784	2714
				2871	2874	2933	2949	2945	2934	2919	2902	2881	2928	2942	2956	2982	2998	2984	2917	2843	2772
				2888	2884	2938	2958	2954	2942	2927	2910	2888	2931	2945	2958	2983	2998	2993	2924	2854	2787
				2906	2898	2955	2982	2975	2966	2952	2937	2913	2973	2986	3003	3024	3042	3043	2979	2906	2846
				2976	2968	3014	3068	3068	3059	3042	3025	2997	2975	2989	3000	3026	3043	3060	3021	2962	2903
				2997	2983	3026	3073	3080	3068	3049	3032	3005	3033	3050	3063	3087	3103	3119	3095	3033	2975
				3026	3011	3053	3096	3106	3098	3078	3064	3039	3011	3022	3038	3060	3074	3089	3071	3010	2955
				3035	3011	3049	3087	3098	3089	3073	3057	3032	3064	3080	3096	3115	3131	3148	3136	3075	3028
				3101	3077	3108	3145	3157	3147	3145	3134	3112	3080	3091	3106	3109	3126	3138	3126	3073	3031
				3105	3075	3109	3134	3151	3141	3140	3124	3105	3134	3147	3161	3166	3183	3199	3199	3150	3106
				3158	3123	3151	3182	3196	3189	3186	3173	3150	3110	3120	3134	3140	3159	3176	3180	3136	3095
				3141	3105	3133	3159	3175	3166	3164	3151	3130	3147	3158	3172	3175	3194	3214	3227	3187	3147
				2591	3165	3186	3204	3217	3208	3204	3192	3173	3129	3138	3151	3157	3176	3193	3208	3178	2525
				2613	3074	3154	3164	3171	3159	3158	3154	3154	3185	3178	3183	3190	3210	3232	3253	3164	2615
				5120 5120 5120>;

			PS_Config_Lmt_Open_Rawdata_N = <
				1069	1071	1073	1083	1092	1079	1072	1092	(-65535)	(-65535)	1060	1039	1051	1064	1078	1095	1095	1066
				999	1002	1017	1040	1062	1059	1053	1047	1033	1025	1038	1041	1051	1054	1059	1063	1047	1019          
				1024	1025	1041	1067	1092	1089	1081	1076	1059	1028	1039	1045	1054	1059	1063	1068	1052	1029        
				1025	1021	1036	1062	1089	1087	1079	1074	1057	1044	1057	1063	1072	1077	1082	1086	1072	1051        
				1036	1033	1048	1076	1103	1100	1091	1087	1068	1031	1043	1048	1057	1063	1067	1071	1060	1039        
				1036	1032	1047	1072	1101	1104	1095	1090	1071	1057	1072	1078	1086	1093	1096	1099	1092	1071        
				1066	1068	1076	1083	1084	1079	1082	1076	1067	1111	1113	1120	1117	1115	1083	1044	1020	997         
				1078	1081	1091	1099	1097	1095	1092	1089	1080	1128	1131	1136	1138	1138	1108	1068	1044	1020        
				1083	1088	1099	1108	1106	1104	1098	1096	1087	1133	1136	1140	1146	1147	1116	1075	1052	1027        
				1099	1104	1117	1124	1123	1122	1117	1111	1101	1149	1153	1161	1164	1168	1134	1095	1072	1045        
				1113	1118	1132	1139	1136	1134	1128	1121	1113	1155	1158	1165	1170	1173	1146	1106	1083	1056        
				1128	1131	1148	1156	1153	1150	1141	1135	1129	1171	1173	1180	1191	1195	1168	1126	1102	1075        
				1129	1133	1158	1165	1164	1159	1151	1146	1142	1172	1171	1177	1188	1192	1166	1128	1095	1069        
				1144	1149	1174	1183	1178	1176	1167	1162	1158	1191	1192	1197	1207	1213	1192	1154	1122	1094        
				1162	1166	1192	1200	1195	1188	1183	1178	1173	1197	1197	1203	1209	1219	1198	1164	1130	1102        
				1176	1180	1204	1217	1209	1206	1197	1193	1186	1218	1220	1227	1236	1243	1228	1192	1158	1131        
				1185	1187	1213	1220	1217	1213	1206	1201	1192	1217	1219	1225	1235	1242	1228	1197	1162	1135        
				1195	1198	1222	1230	1227	1223	1215	1210	1201	1236	1238	1245	1253	1260	1246	1218	1185	1156        
				1212	1213	1238	1241	1241	1239	1231	1224	1216	1237	1242	1248	1258	1263	1252	1224	1193	1163        
				1230	1231	1257	1264	1262	1257	1251	1243	1234	1255	1261	1267	1278	1285	1279	1250	1218	1188        
				1237	1236	1259	1267	1266	1261	1254	1247	1237	1256	1262	1267	1278	1285	1282	1253	1223	1194        
				1245	1242	1266	1278	1275	1271	1265	1258	1248	1274	1279	1287	1296	1303	1304	1276	1245	1219        
				1275	1272	1291	1315	1315	1311	1303	1296	1284	1275	1281	1285	1297	1304	1311	1294	1269	1244        
				1284	1278	1297	1317	1320	1315	1306	1299	1288	1300	1307	1312	1323	1330	1336	1326	1300	1275        
				1297	1290	1308	1327	1331	1327	1319	1313	1302	1290	1295	1302	1311	1317	1324	1316	1290	1266        
				1300	1290	1306	1323	1327	1324	1317	1310	1299	1313	1320	1327	1335	1342	1349	1344	1318	1297        
				1329	1318	1332	1348	1353	1348	1348	1343	1333	1320	1324	1331	1332	1339	1345	1339	1317	1299        
				1330	1318	1332	1343	1350	1346	1345	1339	1330	1343	1348	1354	1357	1364	1371	1371	1350	1331        
				1353	1338	1350	1363	1369	1366	1365	1360	1350	1333	1337	1343	1345	1354	1361	1363	1344	1326        
				1346	1330	1342	1354	1360	1357	1356	1350	1341	1348	1353	1359	1360	1369	1377	1383	1366	1348        
				1110	1356	1365	1373	1378	1375	1373	1368	1360	1341	1345	1350	1353	1361	1368	1375	1362	1082        
				1120	1317	1351	1356	1359	1354	1353	1351	1351	1365	1362	1364	1367	1375	1385	1394	1356	1120        
				(-511) (-511) (-511)>;

			PS_Config_Lmt_FW_Rawdata_P = <
				2234	2231	2227	2244	2248	2241	2244	2240	65535	65535	2224	2219	2233	2213	2266	2263	2251	2245
				2224	2235	2256	2240	2231	2233	2235	2231	2228	2240	2235	2242	2240	2249	2238	2262	2228	2247
				2238	2254	2240	2252	2254	2251	2256	2244	2254	2224	2235	2247	2252	2244	2251	2254	2259	2223
				2251	2245	2228	2237	2244	2237	2233	2233	2226	2247	2214	2224	2233	2226	2217	2235	2249	2231
				2242	2228	2223	2258	2256	2256	2252	2254	2249	2256	2235	2237	2231	2240	2235	2217	2231	2247
				2251	2244	2242	2248	2251	2247	2244	2221	2230	2220	2247	2251	2248	2238	2247	2255	2279	2224
				2254	2228	2240	2238	2242	2266	2245	2231	2245	2248	2241	2244	2244	2220	2226	2254	2219	2254
				2230	2248	2238	2234	2240	2238	2227	2249	2230	2234	2235	2240	2241	2235	2235	2238	2227	2233
				2242	2223	2272	2237	2259	2254	2254	2226	2241	2235	2233	2237	2235	2241	2255	2252	2263	2227
				2241	2240	2265	2252	2259	2251	2265	2242	2252	2247	2231	2228	2234	2251	2242	2237	2238	2231
				2255	2248	2245	2255	2247	2262	2249	2241	2263	2235	2240	2220	2227	2244	2235	2255	2245	2240
				2261	2223	2228	2244	2233	2235	2237	2238	2248	2230	2255	2244	2249	2251	2248	2230	2234	2259
				2213	2263	2266	2247	2245	2235	2259	2251	2247	2221	2254	2230	2227	2238	2235	2249	2247	2242
				2230	2249	2248	2251	2262	2247	2242	2255	2235	2241	2248	2247	2233	2234	2233	2238	2233	2244
				2234	2252	2245	2249	2241	2233	2238	2235	2217	2242	2268	2252	2248	2251	2254	2244	2249	2205
				2230	2234	2230	2230	2252	2268	2263	2255	2258	2251	2231	2226	2220	2223	2244	2244	2244	2227
				2259	2238	2219	2217	2213	2228	2223	2219	2217	2244	2244	2245	2242	2247	2241	2237	2245	2235
				2249	2235	2234	2248	2238	2247	2249	2230	2238	2234	2252	2248	2265	2255	2240	2248	2245	2242
				2242	2258	2266	2258	2252	2248	2248	2251	2237	2245	2217	2217	2221	2220	2223	2230	2210	2256
				2234	2233	2248	2230	2258	2251	2251	2247	2245	2238	2226	2230	2235	2233	2237	2241	2227	2237
				2242	2247	2237	2242	2240	2228	2231	2234	2224	2252	2234	2245	2244	2228	2242	2240	2251	2231
				2262	2237	2220	2230	2223	2248	2231	2228	2248	2247	2223	2235	2244	2214	2226	2230	2231	2244
				2240	2255	2221	2230	2228	2233	2231	2230	2231	2242	2238	2248	2240	2248	2228	2241	2254	2249
				2238	2242	2230	2231	2230	2231	2230	2241	2227	2241	2242	2237	2244	2223	2230	2235	2258	2235
				2223	2228	2235	2224	2240	2254	2249	2233	2258	2240	2241	2255	2242	2235	2240	2242	2235	2235
				2240	2245	2238	2224	2245	2235	2244	2252	2230	2223	2230	2223	2224	2252	2244	2240	2259	2238
				2227	2245	2238	2242	2228	2234	2240	2233	2242	2235	2255	2255	2248	2259	2244	2233	2241	2230
				2254	2240	2252	2256	2247	2249	2242	2235	2238	2259	2252	2233	2228	2240	2227	2238	2231	2237
				2242	2234	2249	2247	2237	2240	2241	2241	2249	2262	2240	2233	2244	2251	2234	2244	2245	2244
				2259	2226	2241	2231	2242	2244	2234	2214	2223	2216	2220	2233	2231	2226	2237	2248	2254	2235
				2235	2247	2221	2219	2244	2251	2248	2247	2233	2219	2223	2221	2217	2233	2224	2228	2261	2245
				2247	2235	2226	2233	2240	2252	2220	2217	2240	2251	2238	2237	2251	2227	2234	2249	2248	2233
				3750 3750 3750>;

			PS_Config_Lmt_FW_Rawdata_N = <
				957	956	954	961	963	960	961	960	(-65535)	(-65535)	953	951	957	948	971	970	964	962
				953	958	967	960	956	957	958	956	955	960	958	961	960	964	959	969	955	963            
				959	966	960	965	966	964	967	961	966	953	958	963	965	961	964	966	968	952            
				964	962	955	958	961	958	957	957	954	963	949	953	957	954	950	958	964	956            
				961	955	952	967	967	967	965	966	964	967	958	958	956	960	958	950	956	963            
				964	961	961	963	964	963	961	952	955	951	963	964	963	959	963	966	976	953            
				966	955	960	959	961	971	962	956	962	963	960	961	961	951	954	966	951	966            
				955	963	959	957	960	959	954	964	955	957	958	960	960	958	958	959	954	957            
				961	952	973	958	968	966	966	954	960	958	957	958	958	960	966	965	970	954            
				960	960	970	965	968	964	970	961	965	963	956	955	957	964	961	958	959	956            
				966	963	962	966	963	969	964	960	970	958	960	951	954	961	958	966	962	960            
				969	952	955	961	957	958	958	959	963	955	966	961	964	964	963	955	957	968            
				948	970	971	963	962	958	968	964	963	952	966	955	954	959	958	964	963	961            
				955	964	963	964	969	963	961	966	958	960	963	963	957	957	957	959	957	961            
				957	965	962	964	960	957	959	958	950	961	972	965	963	964	966	961	964	945            
				955	957	955	955	965	972	970	966	967	964	956	954	951	952	961	961	961	954            
				968	959	951	950	948	955	952	951	950	961	961	962	961	963	960	958	962	958            
				964	958	957	963	959	963	964	955	959	957	965	963	970	966	960	963	962	961            
				961	967	971	967	965	963	963	964	958	962	950	950	952	951	952	955	947	967            
				957	957	963	955	967	964	964	963	962	959	954	955	958	957	958	960	954	958            
				961	963	958	961	960	955	956	957	953	965	957	962	961	955	961	960	964	956            
				969	958	951	955	952	963	956	955	963	963	952	958	961	949	954	955	956	961            
				960	966	952	955	955	957	956	955	956	961	959	963	960	963	955	960	966	964            
				959	961	955	956	955	956	955	960	954	960	961	958	961	952	955	958	967	958            
				952	955	958	953	960	966	964	957	967	960	960	966	961	958	960	961	958	958            
				960	962	959	953	962	958	961	965	955	952	955	952	953	965	961	960	968	959            
				954	962	959	961	955	957	960	957	961	958	966	966	963	968	961	957	960	955            
				966	960	965	967	963	964	961	958	959	968	965	957	955	960	954	959	956	958            
				961	957	964	963	958	960	960	960	964	969	960	957	961	964	957	961	962	961            
				968	954	960	956	961	961	957	949	952	949	951	957	956	954	958	963	966	958            
				958	963	952	951	961	964	963	963	957	951	952	952	950	957	953	955	969	962            
				963	958	954	957	960	965	951	950	960	964	959	958	964	954	957	964	963	957            
				240 240 240>;

			PS_Config_Lmt_FW_CC_P = <
				89	89	89	91	91	91	92	92	65535	65535	95	95	95	93	93	93	93	93
				93	92	92	92	92	92	92	92	95	97	96	96	96	96	96	96	97	97    
				93	92	92	92	92	92	92	92	95	97	95	95	95	95	95	95	96	97    
				93	92	92	92	93	93	93	93	96	99	96	96	96	96	96	96	97	99    
				95	93	92	93	93	93	93	93	96	97	96	96	96	96	96	96	97	99    
				95	93	93	93	93	93	95	95	97	99	96	96	96	96	96	96	97	99    
				96	95	93	93	93	93	93	93	96	100	97	97	97	97	96	96	96	97    
				97	96	96	96	95	95	96	96	99	103	100	100	100	100	100	99	99	100   
				96	95	93	95	93	93	95	95	96	100	97	97	97	97	97	96	96	99    
				99	97	96	96	96	96	96	96	99	103	100	102	102	100	100	99	100	102   
				96	95	93	93	93	93	93	93	96	100	97	99	97	97	97	96	97	99    
				99	97	96	97	96	96	96	96	99	103	100	100	100	100	100	99	100	102   
				96	95	95	95	95	95	95	95	96	100	99	99	99	99	99	97	97	99    
				99	97	97	97	96	96	97	97	100	104	102	102	102	102	102	100	102	103   
				96	95	95	95	95	95	95	95	97	100	99	99	99	99	99	97	99	100   
				99	97	97	97	97	97	97	97	100	103	102	102	102	102	100	100	100	103   
				96	95	95	95	95	95	95	95	97	100	99	99	99	99	99	97	99	100   
				99	97	97	97	97	97	97	97	100	103	102	102	102	102	102	102	102	103   
				97	96	95	96	95	95	95	95	97	102	99	99	100	99	99	99	99	100   
				100	99	97	97	97	97	97	97	100	103	102	102	102	102	102	102	102	103   
				97	96	96	96	96	95	96	96	97	102	99	99	99	99	99	99	99	102   
				100	99	99	99	99	97	97	99	100	104	102	102	102	102	102	102	103	104   
				97	95	95	95	95	95	95	95	97	100	97	97	99	97	99	99	99	100   
				97	95	95	95	95	95	95	95	97	102	99	99	99	99	99	99	100	102   
				97	96	95	96	95	95	95	95	97	100	99	99	99	99	99	99	99	102   
				97	96	96	96	96	95	95	95	97	100	99	99	99	99	99	99	99	102   
				97	96	96	96	96	95	95	95	97	100	99	99	99	99	99	99	99	102   
				96	95	95	95	95	93	93	95	96	100	99	99	99	99	99	99	100	102   
				97	96	95	95	95	95	95	95	97	100	99	99	99	99	99	99	99	102   
				97	96	95	95	95	95	95	95	97	102	99	100	100	99	100	100	100	103   
				92	96	95	95	95	95	95	95	97	102	99	99	99	99	99	99	99	93    
				92	96	96	95	95	95	95	95	99	102	99	99	99	99	99	99	99	95    
				314 314 314>;

			PS_Config_Lmt_FW_CC_N = <
				40	40	40	40	40	40	41	41	(-65535)	(-65535)	42	42	42	42	42	42	42	42
				42	41	41	41	41	41	41	41	42	44	43	43	43	43	43	43	44	44            
				42	41	41	41	41	41	41	41	42	44	42	42	42	42	42	42	43	44            
				42	41	41	41	42	42	42	42	43	44	43	43	43	43	43	43	44	44            
				42	42	41	42	42	42	42	42	43	44	43	43	43	43	43	43	44	44            
				42	42	42	42	42	42	42	42	44	44	43	43	43	43	43	43	44	44            
				43	42	42	42	42	42	42	42	43	45	44	44	44	44	43	43	43	44            
				44	43	43	43	42	42	43	43	44	46	45	45	45	45	45	44	44	45            
				43	42	42	42	42	42	42	42	43	45	44	44	44	44	44	43	43	44            
				44	44	43	43	43	43	43	43	44	46	45	45	45	45	45	44	45	45            
				43	42	42	42	42	42	42	42	43	45	44	44	44	44	44	43	44	44            
				44	44	43	44	43	43	43	43	44	46	45	45	45	45	45	44	45	45            
				43	42	42	42	42	42	42	42	43	45	44	44	44	44	44	44	44	44            
				44	44	44	44	43	43	44	44	45	47	45	45	45	45	45	45	45	46            
				43	42	42	42	42	42	42	42	44	45	44	44	44	44	44	44	44	45            
				44	44	44	44	44	44	44	44	45	46	45	45	45	45	45	45	45	46            
				43	42	42	42	42	42	42	42	44	45	44	44	44	44	44	44	44	45            
				44	44	44	44	44	44	44	44	45	46	45	45	45	45	45	45	45	46            
				44	43	42	43	42	42	42	42	44	45	44	44	45	44	44	44	44	45            
				45	44	44	44	44	44	44	44	45	46	45	45	45	45	45	45	45	46            
				44	43	43	43	43	42	43	43	44	45	44	44	44	44	44	44	44	45            
				45	44	44	44	44	44	44	44	45	47	45	45	45	45	45	45	46	47            
				44	42	42	42	42	42	42	42	44	45	44	44	44	44	44	44	44	45            
				44	42	42	42	42	42	42	42	44	45	44	44	44	44	44	44	45	45            
				44	43	42	43	42	42	42	42	44	45	44	44	44	44	44	44	44	45            
				44	43	43	43	43	42	42	42	44	45	44	44	44	44	44	44	44	45            
				44	43	43	43	43	42	42	42	44	45	44	44	44	44	44	44	44	45            
				43	42	42	42	42	42	42	42	43	45	44	44	44	44	44	44	45	45            
				44	43	42	42	42	42	42	42	44	45	44	44	44	44	44	44	44	45            
				44	43	42	42	42	42	42	42	44	45	44	45	45	44	45	45	45	46            
				41	43	42	42	42	42	42	42	44	45	44	44	44	44	44	44	44	42            
				41	43	43	42	42	42	42	42	44	45	44	44	44	44	44	44	44	42            
				0 0 0>;

			PS_Config_Lmt_FW_Diff_P = <
				50	50	50	50	50	50	50	50	65535	65535	50	50	50	50	50	50	50	50
				50	50	50	50	50	50	50	50	50	50	50	50	50	50	50	50	50	50    
				50	50	50	50	50	50	50	50	50	50	50	50	50	50	50	50	50	50    
				50	50	50	50	50	50	50	50	50	50	50	50	50	50	50	50	50	50    
				50	50	50	50	50	50	50	50	50	50	50	50	50	50	50	50	50	50    
				50	50	50	50	50	50	50	50	50	50	50	50	50	50	50	50	50	50    
				50	50	50	50	50	50	50	50	50	50	50	50	50	50	50	50	50	50    
				50	50	50	50	50	50	50	50	50	50	50	50	50	50	50	50	50	50    
				50	50	50	50	50	50	50	50	50	50	50	50	50	50	50	50	50	50    
				50	50	50	50	50	50	50	50	50	50	50	50	50	50	50	50	50	50    
				50	50	50	50	50	50	50	50	50	50	50	50	50	50	50	50	50	50    
				50	50	50	50	50	50	50	50	50	50	50	50	50	50	50	50	50	50    
				50	50	50	50	50	50	50	50	50	50	50	50	50	50	50	50	50	50    
				50	50	50	50	50	50	50	50	50	50	50	50	50	50	50	50	50	50    
				50	50	50	50	50	50	50	50	50	50	50	50	50	50	50	50	50	50    
				50	50	50	50	50	50	50	50	50	50	50	50	50	50	50	50	50	50    
				50	50	50	50	50	50	50	50	50	50	50	50	50	50	50	50	50	50    
				50	50	50	50	50	50	50	50	50	50	50	50	50	50	50	50	50	50    
				50	50	50	50	50	50	50	50	50	50	50	50	50	50	50	50	50	50    
				50	50	50	50	50	50	50	50	50	50	50	50	50	50	50	50	50	50    
				50	50	50	50	50	50	50	50	50	50	50	50	50	50	50	50	50	50    
				50	50	50	50	50	50	50	50	50	50	50	50	50	50	50	50	50	50    
				50	50	50	50	50	50	50	50	50	50	50	50	50	50	50	50	50	50    
				50	50	50	50	50	50	50	50	50	50	50	50	50	50	50	50	50	50    
				50	50	50	50	50	50	50	50	50	50	50	50	50	50	50	50	50	50    
				50	50	50	50	50	50	50	50	50	50	50	50	50	50	50	50	50	50    
				50	50	50	50	50	50	50	50	50	50	50	50	50	50	50	50	50	50    
				50	50	50	50	50	50	50	50	50	50	50	50	50	50	50	50	50	50    
				50	50	50	50	50	50	50	50	50	50	50	50	50	50	50	50	50	50    
				50	50	50	50	50	50	50	50	50	50	50	50	50	50	50	50	50	50    
				50	50	50	50	50	50	50	50	50	50	50	50	50	50	50	50	50	50    
				50	50	50	50	50	50	50	50	50	50	50	50	50	50	50	50	50	50    
				75 75 75>;

			PS_Config_Lmt_FW_Diff_N = <
				(-50)	(-50)	(-50)	(-50)	(-50)	(-50)	(-50)	(-50)	(-65535)	(-65535)	(-50)	(-50)	(-50)	(-50)	(-50)	(-50)	(-50)	(-50)
				(-50)	(-50)	(-50)	(-50)	(-50)	(-50)	(-50)	(-50)	(-50)	(-50)	(-50)	(-50)	(-50)	(-50)	(-50)	(-50)	(-50)	(-50)        
				(-50)	(-50)	(-50)	(-50)	(-50)	(-50)	(-50)	(-50)	(-50)	(-50)	(-50)	(-50)	(-50)	(-50)	(-50)	(-50)	(-50)	(-50)        
				(-50)	(-50)	(-50)	(-50)	(-50)	(-50)	(-50)	(-50)	(-50)	(-50)	(-50)	(-50)	(-50)	(-50)	(-50)	(-50)	(-50)	(-50)        
				(-50)	(-50)	(-50)	(-50)	(-50)	(-50)	(-50)	(-50)	(-50)	(-50)	(-50)	(-50)	(-50)	(-50)	(-50)	(-50)	(-50)	(-50)        
				(-50)	(-50)	(-50)	(-50)	(-50)	(-50)	(-50)	(-50)	(-50)	(-50)	(-50)	(-50)	(-50)	(-50)	(-50)	(-50)	(-50)	(-50)        
				(-50)	(-50)	(-50)	(-50)	(-50)	(-50)	(-50)	(-50)	(-50)	(-50)	(-50)	(-50)	(-50)	(-50)	(-50)	(-50)	(-50)	(-50)        
				(-50)	(-50)	(-50)	(-50)	(-50)	(-50)	(-50)	(-50)	(-50)	(-50)	(-50)	(-50)	(-50)	(-50)	(-50)	(-50)	(-50)	(-50)        
				(-50)	(-50)	(-50)	(-50)	(-50)	(-50)	(-50)	(-50)	(-50)	(-50)	(-50)	(-50)	(-50)	(-50)	(-50)	(-50)	(-50)	(-50)        
				(-50)	(-50)	(-50)	(-50)	(-50)	(-50)	(-50)	(-50)	(-50)	(-50)	(-50)	(-50)	(-50)	(-50)	(-50)	(-50)	(-50)	(-50)        
				(-50)	(-50)	(-50)	(-50)	(-50)	(-50)	(-50)	(-50)	(-50)	(-50)	(-50)	(-50)	(-50)	(-50)	(-50)	(-50)	(-50)	(-50)        
				(-50)	(-50)	(-50)	(-50)	(-50)	(-50)	(-50)	(-50)	(-50)	(-50)	(-50)	(-50)	(-50)	(-50)	(-50)	(-50)	(-50)	(-50)        
				(-50)	(-50)	(-50)	(-50)	(-50)	(-50)	(-50)	(-50)	(-50)	(-50)	(-50)	(-50)	(-50)	(-50)	(-50)	(-50)	(-50)	(-50)        
				(-50)	(-50)	(-50)	(-50)	(-50)	(-50)	(-50)	(-50)	(-50)	(-50)	(-50)	(-50)	(-50)	(-50)	(-50)	(-50)	(-50)	(-50)        
				(-50)	(-50)	(-50)	(-50)	(-50)	(-50)	(-50)	(-50)	(-50)	(-50)	(-50)	(-50)	(-50)	(-50)	(-50)	(-50)	(-50)	(-50)        
				(-50)	(-50)	(-50)	(-50)	(-50)	(-50)	(-50)	(-50)	(-50)	(-50)	(-50)	(-50)	(-50)	(-50)	(-50)	(-50)	(-50)	(-50)        
				(-50)	(-50)	(-50)	(-50)	(-50)	(-50)	(-50)	(-50)	(-50)	(-50)	(-50)	(-50)	(-50)	(-50)	(-50)	(-50)	(-50)	(-50)        
				(-50)	(-50)	(-50)	(-50)	(-50)	(-50)	(-50)	(-50)	(-50)	(-50)	(-50)	(-50)	(-50)	(-50)	(-50)	(-50)	(-50)	(-50)        
				(-50)	(-50)	(-50)	(-50)	(-50)	(-50)	(-50)	(-50)	(-50)	(-50)	(-50)	(-50)	(-50)	(-50)	(-50)	(-50)	(-50)	(-50)        
				(-50)	(-50)	(-50)	(-50)	(-50)	(-50)	(-50)	(-50)	(-50)	(-50)	(-50)	(-50)	(-50)	(-50)	(-50)	(-50)	(-50)	(-50)        
				(-50)	(-50)	(-50)	(-50)	(-50)	(-50)	(-50)	(-50)	(-50)	(-50)	(-50)	(-50)	(-50)	(-50)	(-50)	(-50)	(-50)	(-50)        
				(-50)	(-50)	(-50)	(-50)	(-50)	(-50)	(-50)	(-50)	(-50)	(-50)	(-50)	(-50)	(-50)	(-50)	(-50)	(-50)	(-50)	(-50)        
				(-50)	(-50)	(-50)	(-50)	(-50)	(-50)	(-50)	(-50)	(-50)	(-50)	(-50)	(-50)	(-50)	(-50)	(-50)	(-50)	(-50)	(-50)        
				(-50)	(-50)	(-50)	(-50)	(-50)	(-50)	(-50)	(-50)	(-50)	(-50)	(-50)	(-50)	(-50)	(-50)	(-50)	(-50)	(-50)	(-50)        
				(-50)	(-50)	(-50)	(-50)	(-50)	(-50)	(-50)	(-50)	(-50)	(-50)	(-50)	(-50)	(-50)	(-50)	(-50)	(-50)	(-50)	(-50)        
				(-50)	(-50)	(-50)	(-50)	(-50)	(-50)	(-50)	(-50)	(-50)	(-50)	(-50)	(-50)	(-50)	(-50)	(-50)	(-50)	(-50)	(-50)        
				(-50)	(-50)	(-50)	(-50)	(-50)	(-50)	(-50)	(-50)	(-50)	(-50)	(-50)	(-50)	(-50)	(-50)	(-50)	(-50)	(-50)	(-50)        
				(-50)	(-50)	(-50)	(-50)	(-50)	(-50)	(-50)	(-50)	(-50)	(-50)	(-50)	(-50)	(-50)	(-50)	(-50)	(-50)	(-50)	(-50)        
				(-50)	(-50)	(-50)	(-50)	(-50)	(-50)	(-50)	(-50)	(-50)	(-50)	(-50)	(-50)	(-50)	(-50)	(-50)	(-50)	(-50)	(-50)        
				(-50)	(-50)	(-50)	(-50)	(-50)	(-50)	(-50)	(-50)	(-50)	(-50)	(-50)	(-50)	(-50)	(-50)	(-50)	(-50)	(-50)	(-50)        
				(-50)	(-50)	(-50)	(-50)	(-50)	(-50)	(-50)	(-50)	(-50)	(-50)	(-50)	(-50)	(-50)	(-50)	(-50)	(-50)	(-50)	(-50)        
				(-50)	(-50)	(-50)	(-50)	(-50)	(-50)	(-50)	(-50)	(-50)	(-50)	(-50)	(-50)	(-50)	(-50)	(-50)	(-50)	(-50)	(-50)        
				(-75) (-75) (-75)>;

			PS_Config_Diff_Test_Frame = <50>;
		};
	};
	/*HS50 code for SR-QL3095-01-358 by yuanliding at 2020/07/31 end*/
	himax@2{
		compatible = "himax,hxcommon";
		reg = <0x2>;
		spi-max-frequency = <10000000>;
		interrupt-parent = <&tlmm>;
		lcm_lab-supply = <&lcdb_ldo_vreg>;//Adding Power Properties
		lcm_ibb-supply = <&lcdb_ncp_vreg>;
		interrupts = <65 0x02>;
		himax,panel-coords = <0 720 0 1600>;
		himax,display-coords = <0 720 0 1600>;
		himax,irq-gpio = <&tlmm 65 0x02>;
		himax,rst-gpio = <&tlmm 64 0x01>;
		himax,touch_info = <34 16 0 720 1600 10 0 1>;
		himax,vdd_1v8_always_on;
		report_type = <1>;
	};
	chipone_tddi@3{
        compatible = "tddi,chipone-tddi";
        reg = <0x03>;
	spi-max-frequency = <10000000>;
        interrupt-parent = <&tlmm>;
        interrupts = <65 0x2>;
        chipone,rst-gpio = <&tlmm 64 0x01>;
        chipone,irq-gpio = <&tlmm 65 0x02>;
        chipone,x-res = <720>;
        chipone,y-res = <1600>;
        lcm_lab-supply = <&lcdb_ldo_vreg>;//Adding Power Properties
        lcm_ibb-supply = <&lcdb_ncp_vreg>;
		/* selftest settings */
		chipone,test-reset-pin;
		chipone,test-int-pin;

		chipone,test-rawdata;
		chipone,test-rawdata-frames = <1>;
		chipone,rawdata-min = <700>;
		chipone,rawdata-max = <1500>;

		chipone,test-noise;
		chipone,test-noise-frames = <16>;
		chipone,noise-max = <50>;

		chipone,test-open;
		chipone,open-min = <200>;

		chipone,test-short;
		chipone,short-min = <200>;

		chipone,test-compensate-cap;
		chipone,compensate-cap-min = <20>;
		chipone,compensate-cap-max = <110>;
        /* Charger detect */
        chipone,touch-charger-detect-enable;
        chipone,touch-charger-detect-type = "notify"; /* notify, poll */
        chipone,touch-charger-detect-psy-name = "usb";
        chipone,touch-charger-detect-psp = "POWER_SUPPLY_PROP_ONLINE";
        chipone,touch-charger-detect-psp-poll-interval = <1000>;
    };
};

&spi3_cs0_sleep{
 /delete-node/ config;
 config {
  pins = "gpio10";
  drive-strength = <2>;
  //bias-disable = <0>;
  bias-pull-up;
 };
};

/* HS70 code for HS70-133 by liufurong at 2019/10/31 start */
&tlmm {
	default {
		ts_int_default: ts_int_default {
			mux {
				pins = "gpio65";
				function = "gpio";
			};
			config {
				pins = "gpio65";
				drive-strength = <8>;
				input-enable;
				bias-pull-up;
			};
		};
	};
	int-output-high {
		ts_int_output_high: ts_int_output_high {
			mux {
				pins = "gpio65";
				function = "gpio";
			};
			config {
				pins = "gpio65";
				drive-strength = <8>;
				output-high;
				bias-pull-up;
			};
		};
	};
	int-output-low {
		ts_int_output_low: ts_int_output_low {
			mux {
				pins = "gpio65";
				function = "gpio";
			};
			config {
				pins = "gpio65";
				drive-strength = <8>;
				bias-pull-down;
				output-low;
			};
		};
	};
	int-input {
		ts_int_input: ts_int_input {
			mux {
				pins = "gpio65";
				function = "gpio";
			};
			config {
				pins = "gpio65";
				drive-strength = <8>;
				input-enable;
				bias-pull-up;
			};
		};
	};
};
/* HS70 code for HS70-133 by liufurong at 2019/10/31 end */
